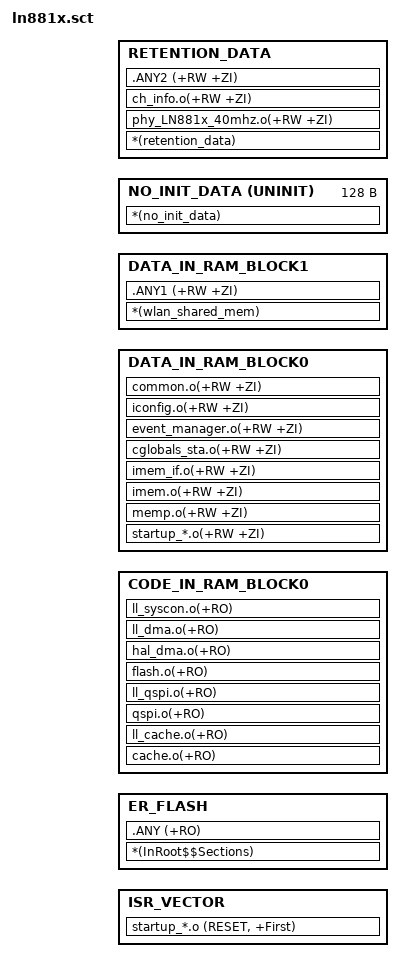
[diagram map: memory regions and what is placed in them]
#! armcc -E
#include "..\flash_partition_table.h"
#include "..\..\..\include\cpu\ARM_CM4F\ln88xx\mem_map_ln881x.h"


LR_FLASH FLASH_BASE+PRIMARY_PARTITION_OFFSET PRIMARY_PATTITION_SIZE  {    ; load region size_region

  ISR_VECTOR RAM_BLOCK0_BASE ALIGN 0x100{
	  startup_*.o (RESET, +First)
  }

  ER_FLASH FLASH_BASE+PRIMARY_PARTITION_OFFSET + ImageLength(ISR_VECTOR) PRIMARY_PATTITION_SIZE {  ; load address = execution address
	  *(InRoot$$Sections)
	  .ANY (+RO)
  }

  CODE_IN_RAM_BLOCK0 ImageLimit(ISR_VECTOR){
	  cache.o(+RO)
	  ll_cache.o(+RO)
	  qspi.o(+RO)
	  ll_qspi.o(+RO)
	  flash.o(+RO)
	  hal_dma.o(+RO)
	  ll_dma.o(+RO)
	  ll_syscon.o(+RO)
  }

  DATA_IN_RAM_BLOCK0 +0 (RAM_BLOCK0_SIZE - ImageLength(ISR_VECTOR) - ImageLength(CODE_IN_RAM_BLOCK0)) {
      startup_*.o(+RW +ZI)
      memp.o(+RW +ZI)
      imem.o(+RW +ZI)
      imem_if.o(+RW +ZI)
      cglobals_sta.o(+RW +ZI)
      event_manager.o(+RW +ZI)
      iconfig.o(+RW +ZI)
      common.o(+RW +ZI)
  }

  ;OS_HEAP_IN_RAM_BLOCK0 ImageLimit(DATA_IN_RAM_BLOCK0) {

  ;}

  DATA_IN_RAM_BLOCK1 RAM_BLOCK1_BASE (RAM_BLOCK1_SIZE){
      *(wlan_shared_mem)
	  .ANY1 (+RW +ZI)
  }

  ;OS_HEAP_IN_RAM_BLOCK1 ImageLimit(DATA_IN_RAM_BLOCK1) {

  ;}
  
  NO_INIT_DATA RETENTION_MEM_BASE  UNINIT 0x80{
      *(no_init_data)
  }

  RETENTION_DATA RETENTION_MEM_BASE+0x80  ANY_SIZE 0x2000-0x80-128 RETENTION_MEM_SIZE-0x80{
      *(retention_data)
      phy_LN881x_40mhz.o(+RW +ZI)
      ch_info.o(+RW +ZI)
      
      .ANY2 (+RW +ZI)
  }
}	
	

